# STM32MP21_CM33 register map
File version: 0.4
CPU: CM33 r0p1, little endian, MPU, FPU, vendor SysTick, 8 interrupt priority bits
Registers are 32-bit, read-write, reset 0x0 unless marked. A register's access mark holds for its fields unless they carry their own. Offsets are from the block's base; [hi:lo] are bit positions; {n}, {i} and the like mark numbered series.

## RNG1 — RNG address block description
Base 0x42030800
Same registers: RNG2 0x42020000, RNG2_S 0x52020000, RNG1_S 0x52030800
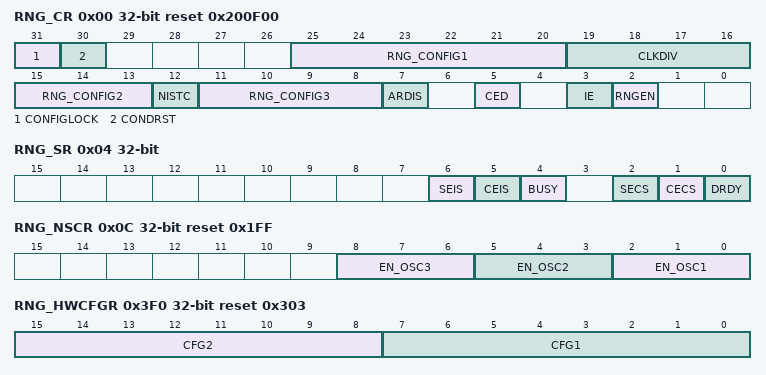
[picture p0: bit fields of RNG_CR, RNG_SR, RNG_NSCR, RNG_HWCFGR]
0x00 RNG_CR reset 0x200F00 — RNG control register
  [31] CONFIGLOCK — RNG Config lock
    0=Writes to the RNG_NSCR, RNG_HTCR and RNG_CR configuration bits [29:4] are allowed; 1=Writes to the RNG_NSCR, RNG_HTCR and RNG_CR configuration bits [29:4] are ignored until the next RNG reset
  [30] CONDRST — Conditioning soft reset
  [25:20] RNG_CONFIG1 — RNG configuration 1
  [19:16] CLKDIV — Clock divider factor
    0=internal RNG clock after divider is similar to incoming RNG clock; 1=two RNG clock cycles per internal RNG clock; 2=2less thansup>2less than/sup> (= 4) RNG clock cycles per internal RNG clock; 15=2less thansup>15less than/sup> RNG clock cycles per internal clock (for example
  [15:13] RNG_CONFIG2 — RNG configuration 2
  [12] NISTC — NIST custom
    0=Hardware default values for NIST compliant RNG; 1=Custom values for NIST compliant RNG
  [11:8] RNG_CONFIG3 — RNG configuration 3
  [7] ARDIS — Auto reset disable
    0=Auto-reset enabled; 1=Auto-reset disabled
  [5] CED — Clock error detection
    0=Clock error detection enabled; 1=Clock error detection is disabled
  [3] IE — Interrupt enable
    0=RNG interrupt is disabled; 1=RNG interrupt is enabled
  [2] RNGEN — True random number generator enable
    0=True random number generator disabled; 1=True random number generator enabled
0x04 RNG_SR — RNG status register
  [6] SEIS — Seed error interrupt status
    0=No faulty sequence detected; 1=At least one faulty sequence is detected
  [5] CEIS — Clock error interrupt status
    0=The RNG clock is correct (fless thansub>RNGCLKless than/sub>> fless thansub>HCLKless than/sub>/32); 1=The RNG clock before the internal divider is detected too slow (fless thansub>RNGCLKless than/sub>less than fless thansub>HCLKless than/sub>/32)
  [4] BUSY ro
    0=Idle; 1=Busy
  [2] SECS ro — Seed error current status
    0=No faulty sequence has currently been detected; 1=At least one of the following faulty sequence has been detected:
  [1] CECS ro — Clock error current status
    0=The RNG clock is correct (fless thansub>RNGCLKless than/sub>> fless thansub>HCLKless than/sub>/32); 1=The RNG clock is too slow (fless thansub>RNGCLKless than/sub>less than fless thansub>HCLKless than/sub>/32)
  [0] DRDY ro — Data ready
    0=No valid random data ready; 1=Valid random data ready
0x08 RNG_DR ro — RNG data register
  [31:0] RNDATA — Random data
0x0C RNG_NSCR reset 0x1FF — RNG noise source control register
  [8:6] EN_OSC3 — Each bit drives one oscillator enable signal input of instance number 3, gated with the RNGEN bit in RNG_CR (set bit to enable the oscillator).
  [5:3] EN_OSC2 — Each bit drives one oscillator enable signal input of instance number 2, gated with the RNGEN bit in RNG_CR (set bit to enable the oscillator).
  [2:0] EN_OSC1 — Each bit drives one oscillator enable signal input of instance number 1, gated with the RNGEN bit in RNG_CR (set bit to enable the oscillator).
0x10 RNG_HTCR0 reset 0x72AC — RNG health test control register 0
  [31:0] HTCFG — health test configuration
{0x10+4i} RNG_HTCR{i} reset 0xFFFF (i=1..3) — RNG health test control register {i}
  [31:0] HTCFG — health test configuration
0x3F0 RNG_HWCFGR ro reset 0x303 — RNG hardware configuration register
  [15:8] CFG2 — Hardware generic 2
  [7:0] CFG1 — Hardware generic 1
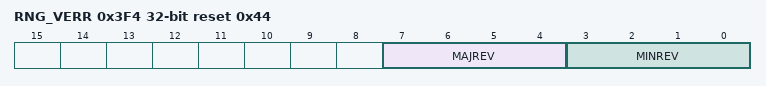
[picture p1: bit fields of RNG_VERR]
0x3F4 RNG_VERR ro reset 0x44 — RNG version register
  [7:4] MAJREV — RNG major revision
  [3:0] MINREV — RNG minor revision
0x3F8 RNG_IPIDR ro reset 0x170041 — RNG identification register
  [31:0] ID — RNG identification code
0x3FC RNG_SIDR ro reset 0xA3C5DD01 — RNG size identification register
  [31:0] SID — RNG size identification code
